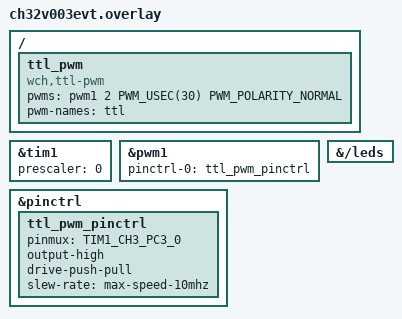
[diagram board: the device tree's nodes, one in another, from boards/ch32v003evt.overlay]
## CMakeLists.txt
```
# SPDX-License-Identifier: Apache-2.0

cmake_minimum_required(VERSION 3.20.0)

find_package(Zephyr REQUIRED HINTS $ENV{ZEPHYR_BASE})
project(wch32_gpio)

target_sources(app PRIVATE src/main.c)
```

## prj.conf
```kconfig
CONFIG_SIZE_OPTIMIZATIONS=y

CONFIG_GPIO=y
CONFIG_PWM=y

# Not used by this application: board defconfig enables these, so they
# must be turned off explicitly to keep them out of the tight 16K ROM.
CONFIG_SERIAL=n
CONFIG_CONSOLE=n
CONFIG_UART_CONSOLE=n
CONFIG_PRINTK=n
CONFIG_BOOT_BANNER=n
CONFIG_ASSERT=n
```

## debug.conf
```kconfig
# Debug build: west build -b ch32v003evt -- -DEXTRA_CONF_FILE=debug.conf
#
# -Og keeps enough structure that GDB can reliably show local variables
# (prj.conf uses -Os for the release build, which is small but tends to
# optimize locals away — "value optimized out" in gdb).
#
# This alone uses ~90% of the 16K ROM, so it is NOT combined with
# serial.conf by default: DEBUG_OPTIMIZATIONS + printk/UART together
# overflow ROM by ~2.8K on this chip. Use debug.conf when you need to
# single-step and inspect variables; use serial.conf when you need
# printk output instead. Combine only after trimming app code to make
# room for both.
CONFIG_DEBUG_OPTIMIZATIONS=y
```

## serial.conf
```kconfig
# Optional UART console: west build -b ch32v003evt -- -DEXTRA_CONF_FILE=serial.conf
#
# Re-enables USART1 (already pinctrl'd as zephyr,console in the board's
# .dts) so printk() reaches the serial terminal at 115200 8N1. Keeps
# -Os (prj.conf) rather than -Og so it still fits in the 16K ROM;
# see debug.conf for why the two aren't combined by default.
CONFIG_SERIAL=y
CONFIG_CONSOLE=y
CONFIG_UART_CONSOLE=y
CONFIG_PRINTK=y
CONFIG_BOOT_BANNER=n
CONFIG_CBPRINTF_NANO=y
```

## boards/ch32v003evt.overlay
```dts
/*
 * Copyright (c) 2026 Alberto Venzo <alberto.venzo@spiralengineering.it>
 * SPDX-License-Identifier: Apache-2.0
 */
 
 #include <zephyr/dt-bindings/pinctrl/ch32v003-pinctrl.h>

/ {

  ttl_pwm: ttl_pwm {
    compatible = "wch,ttl-pwm";
    /* Channel index is 0-based in the wch,adtm-pwm driver: 2 = TIM1 CH3 (PC3). */
    pwms = <&pwm1 2 PWM_USEC(30) PWM_POLARITY_NORMAL>;
    pwm-names = "ttl";
  };

};
 
&tim1 {
  status = "okay";
  /* prescaler = 0 -> 48 MHz timer clock, matching the known-working
   * bare-metal SPL reference (PSC=0) instead of the SoC dtsi's default
   * prescaler of 1 (24 MHz). */
  prescaler = <0>;
};

&pwm1 {
  status = "okay";
  pinctrl-0 = <&ttl_pwm_pinctrl>;
  pinctrl-names = "default";
};

&pinctrl {
  ttl_pwm_pinctrl: ttl_pwm_pinctrl {
    pinmux = <TIM1_CH3_PC3_0>;
    output-high;
    drive-push-pull;
    slew-rate = "max-speed-10mhz";
  };
};

/* heartbeat toggle on PD4, wired up as led0 by the board's own .dts */
&{/leds} {
  status = "okay";
};
```

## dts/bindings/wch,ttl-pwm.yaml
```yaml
description: Custom TTL PWM output node

compatible: "wch,ttl-pwm"

include: base.yaml

properties:
  pwms:
    type: phandle-array
    required: true
    description: |
      PWM channel to use. Format should be <&pwm_node channel period_in_hz flags>.

  pwm-names:
    type: string-array
    description: |
      Name of the PWM channel. Useful if a device has multiple PWMs.
```

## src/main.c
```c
#include <zephyr/kernel.h>
#include <zephyr/sys/printk.h>
#include <zephyr/drivers/gpio.h>
#include <zephyr/drivers/pwm.h>

/* TIM1 channel 3 / PC3, see boards/ch32v003evt.overlay */
static const struct pwm_dt_spec ttl = PWM_DT_SPEC_GET(DT_NODELABEL(ttl_pwm));

/* PD4, wired up by the board's own .dts, enabled in boards/ch32v003evt.overlay */
static const struct gpio_dt_spec heartbeat = GPIO_DT_SPEC_GET(DT_ALIAS(led0), gpios);

/*
 * Fixed 25 us / 50% duty, matching the known-working bare-metal SPL
 * reference exactly: ConfigurePWM(1200-1, 0, 600) at 48 MHz (prescaler=0,
 * see boards/ch32v003evt.overlay) is 1200 cycles = 25 us period, 600
 * cycles = 12.5 us pulse.
 */
#define PERIOD_NS PWM_NSEC(25000)
#define PULSE_NS  PWM_NSEC(12500)

#define WCH_GPIOC_CFGLR (*(volatile uint32_t *)(0x40011000))

int main(void)
{
    WCH_GPIOC_CFGLR = 0x3883B443U;
    if (!device_is_ready(ttl.dev)) {
        return -ENODEV;
    }

    if (!device_is_ready(heartbeat.port)) {
        return -ENODEV;
    }
    gpio_pin_configure_dt(&heartbeat, GPIO_OUTPUT_INACTIVE);

    pwm_set_dt(&ttl, PERIOD_NS, PULSE_NS);

    printk("PWM + heartbeat running\n");

    while (1) {
        gpio_pin_toggle_dt(&heartbeat);
        k_msleep(20);
    }

    return 0;
}
```
